AUTOSAR XML (schema 4-2-2)
package /ComponentTypes
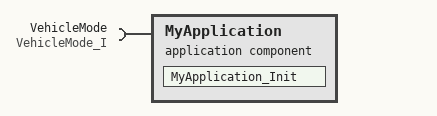
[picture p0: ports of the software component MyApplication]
  application sw component type MyApplication
    require port VehicleMode: mode-switch-receiver-com-spec{enhanced-mode-api=false, mode-group=mode, supports-asynchronous-mode-switch=false}, required-interface=VehicleMode_I
    behavior MyApplication_InternalBehavior: port-api-option{enable-take-address=false, indirect-api=false, port=VehicleMode}
      swc mode switch event MST_MyApplication_Init: start-on-event=MyApplication_Init, activation=ON-ENTRY, mode=VehicleMode.mode.ACCESSORY
      runnable MyApplication_Init
  swc implementation MyApplication_Implementation: behavior=MyApplication_InternalBehavior
